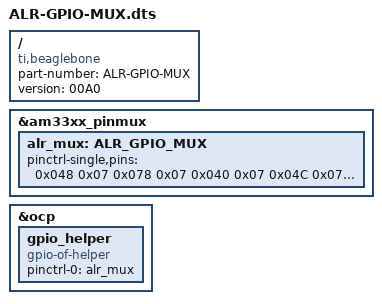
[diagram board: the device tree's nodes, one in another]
/*  
* Copyright (C) 2012 Texas Instruments Incorporated - http://www.ti.com/
*
* This program is free software; you can redistribute it and/or modify
* it under the terms of the GNU General Purpose License Version 2 as
* published by the Free Software Foundation
*
* Original from: github.com/jadonk/validation-scripts/blob/master/test-capemgr/ 
*
* Modified by Derek Molloy for the example on www.derekmolloy.ie
* that maps GPIO pins for the example
*/

/dts-v1/;
/plugin/;

/{
       compatible = "ti,beaglebone", "ti,beaglebone-black";
       part-number = "ALR-GPIO-MUX";
       version = "00A0";

       fragment@0 {
             target = <&am33xx_pinmux>;
           
             __overlay__ {
                  alr_mux: ALR_GPIO_MUX {
			pinctrl-single,pins = <
                                /* OUTPUTS ALL PULLDOWN */
                                0x048 0x07  // P9_14 PINS$18  GPIO1_18 = 50  Output Mode7 pulldown
                                0x078 0x07  // P9_12 PINS$30  GPIO1_28 = 60  Output Mode7 pulldown
                                0x040 0x07  // P9_15 PINS$16  GPIO1_16 = 48  Output Mode7 pulldown
                                0x04C 0x07  // P9_16 PINS$19  GPIO1_19 = 51  Output Mode7 pulldown
                                0x154 0x07  // P9_21 PINS$85  GPIO0_03 = 03  Output Mode7 pulldown
                                0x150 0x07  // P9_22 PINS$84  GPIO0_02 = 02  Output Mode7 pulldown
                                0x044 0x07  // P9_23 PINS$17  GPIO1_17 = 49  Output Mode7 pulldown
                                0x1AC 0x07  // P9_25 PINS$107 GPIO3_21 = 117 Output Mode7 pulldown
                                /* INPUTS ALL PULLUP    */
                                0x1A4 0x37  // P9_27 PINS$105 GPIO3_19 = 115 Output Mode7 pulldown
                                0x090 0x37  // P8_07 PINS$36  GPIO2_02 = 66 Input Mode7 pullup 
                                0x094 0x37  // P8_08 PINS$37  GPIO2_03 = 67 Input Mode7 pullup
                                0x09C 0x37  // P8_09 PINS$39  GPIO2_05 = 69 Input Mode7 pullup
                                0x098 0x37  // P8_10 PINS$38  GPIO2_04 = 68 Input Mode7 pullup
                                0x034 0x37  // P8_11 PINS$13  GPIO1_13 = 45 Input Mode7 pullup
                                0x030 0x37  // P8_12 PINS$12  GPIO1_12 = 44 Input Mode7 pullup
                                0x024 0x37  // P8_13 PINS$9   GPIO0_23 = 23 Input Mode7 pullup
                                0x028 0x37  // P8_14 PINS$10  GPIO0_26 = 26 Input Mode7 pullup
                                0x03C 0x37  // P8_15 PINS$15  GPIO1_15 = 47 Input Mode7 pullup
                                0x038 0x37  // P8_16 PINS$14  GPIO1_14 = 46 Input Mode7 pullup
                                0x02C 0x37  // P8_17 PINS$11  GPIO0_27 = 27 Input Mode7 pullup
                               /* OUTPUT  GPIO(mode7) 0x07 pulldown, 0x17 pullup, 0x?f no pullup/down */
			       /* INPUT   GPIO(mode7) 0x27 pulldown, 0x37 pullup, 0x?f no pullup/down */
			>;
		  };
             };
       };

       fragment@1 {
		target = <&ocp>;
		__overlay__ {
			gpio_helper {
				compatible = "gpio-of-helper";
				status = "okay";
				pinctrl-names = "default";
				pinctrl-0 = <&alr_mux>;
			};
		};
	};
};
